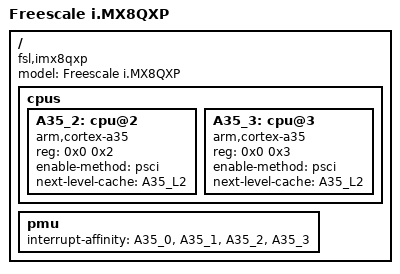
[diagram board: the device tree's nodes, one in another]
// SPDX-License-Identifier: GPL-2.0+
/*
 * Copyright 2018 NXP
 *
 * This program is free software; you can redistribute it and/or
 * modify it under the terms of the GNU General Public License
 * as published by the Free Software Foundation; either version 2
 * of the License, or (at your option) any later version.
 *
 * This program is distributed in the hope that it will be useful,
 * but WITHOUT ANY WARRANTY; without even the implied warranty of
 * MERCHANTABILITY or FITNESS FOR A PARTICULAR PURPOSE.  See the
 * GNU General Public License for more details.
 */

#include "fsl-imx8dxp.dtsi"

/ {
	model = "Freescale i.MX8QXP";
	compatible = "fsl,imx8qxp";

	cpus {
		A35_2: cpu@2 {
			device_type = "cpu";
			compatible = "arm,cortex-a35";
			reg = <0x0 0x2>;
			enable-method = "psci";
			next-level-cache = <&A35_L2>;
		};

		A35_3: cpu@3 {
			device_type = "cpu";
			compatible = "arm,cortex-a35";
			reg = <0x0 0x3>;
			enable-method = "psci";
			next-level-cache = <&A35_L2>;
		};
	};

	pmu {
		interrupt-affinity = <&A35_0>, <&A35_1>, <&A35_2>, <&A35_3>;
	};
};

&A35_2 {
	device_type = "cpu";
};

&A35_3 {
	device_type = "cpu";
};
